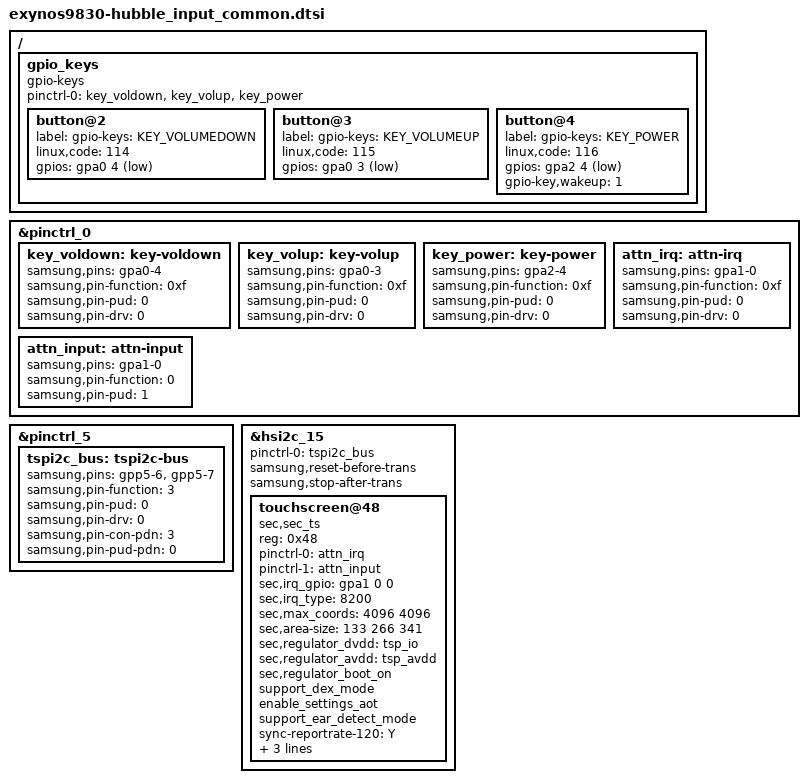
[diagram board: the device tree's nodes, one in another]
/*
 * SAMSUNG EXYNOS9830 input device tree source
 *
 * Copyright (c) 2019 Samsung Electronics Co., Ltd.
 *		http://www.samsung.com
 *
 * This program is free software; you can redistribute it and/or modify
 * it under the terms of the GNU General Public License version 2 as
 * published by the Free Software Foundation.
*/

/ {

	fragment@model {
		target-path = "/";
		__overlay__ {
			gpio_keys {
				status = "okay";
				compatible = "gpio-keys";
				pinctrl-names = "default";
				pinctrl-0 = <&key_voldown &key_volup &key_power>;

				button@2 {
					label = "gpio-keys: KEY_VOLUMEDOWN";
					linux,code = <114>;
					gpios = <&gpa0 4 0xf>;
				};
				button@3 {
					label = "gpio-keys: KEY_VOLUMEUP";
					linux,code = <115>;
					gpios = <&gpa0 3 0xf>;
				};
				button@4 {
					label = "gpio-keys: KEY_POWER";
					linux,code = <116>;
					gpios = <&gpa2 4 0xf>;
					gpio-key,wakeup = <1>;
				};
			};
		}; /* end of __overlay__ */
	}; /* end of fragment */
}; /* end of root */

&pinctrl_0 {
	key_voldown: key-voldown {
		samsung,pins = "gpa0-4";
		samsung,pin-function = <0xf>;
		samsung,pin-pud = <0>;
		samsung,pin-drv = <0>;
	};

	key_volup: key-volup {
		samsung,pins = "gpa0-3";
		samsung,pin-function = <0xf>;
		samsung,pin-pud = <0>;
		samsung,pin-drv = <0>;
	};

	key_power: key-power {
		samsung,pins = "gpa2-4";
		samsung,pin-function = <0xf>;
		samsung,pin-pud = <0>;
		samsung,pin-drv = <0>;
	};

	attn_irq: attn-irq {
		samsung,pins = "gpa1-0";
		samsung,pin-function = <0xf>;
		samsung,pin-pud = <0>;
		samsung,pin-drv = <0>;
	};

	attn_input: attn-input {
		samsung,pins = "gpa1-0";
		samsung,pin-function = <0>;
		samsung,pin-pud = <1>;
	};
};

&pinctrl_5 {
	tspi2c_bus: tspi2c-bus {
		samsung,pins = "gpp5-6", "gpp5-7";
		samsung,pin-function = <3>;
		samsung,pin-pud = <0>;
		samsung,pin-drv = <0>;
		samsung,pin-con-pdn = <3>;
		samsung,pin-pud-pdn = <0>;
	};
};

&hsi2c_15 {
	#address-cells = <1>;
	#size-cells = <0>;
	pinctrl-names = "default";
	pinctrl-0 = <&tspi2c_bus>;
	status = "okay";
	samsung,reset-before-trans;
	samsung,stop-after-trans;	/* LSI IC ONLY */
	touchscreen@48 {
		compatible = "sec,sec_ts";
		reg = <0x48>;
		pinctrl-names = "on_state", "off_state";
		pinctrl-0 = <&attn_irq>;
		pinctrl-1 = <&attn_input>;
		sec,irq_gpio = <&gpa1 0 0>;
		sec,irq_type = <8200>;
		sec,max_coords = <4096 4096>;
		sec,area-size = <133 266 341>; /* indicator: 24dp navigator:48dp edge:60px dpi=320 */
		sec,regulator_dvdd = "tsp_io";
		sec,regulator_avdd = "tsp_avdd";
		sec,regulator_boot_on;
		support_dex_mode;
		enable_settings_aot;
		support_ear_detect_mode;
		sync-reportrate-120 = "Y";
		support_fod;
		support_vrr;
		support_open_short_test;
	};
};
